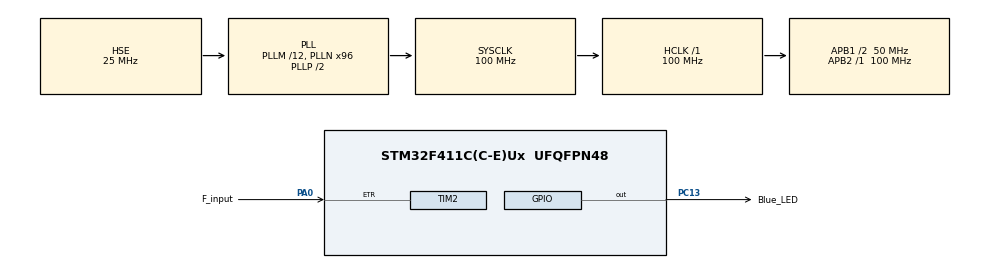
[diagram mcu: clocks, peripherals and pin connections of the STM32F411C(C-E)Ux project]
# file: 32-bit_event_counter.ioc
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Mcu.Family=STM32F4
Mcu.Name=STM32F411C(C-E)Ux
Mcu.Package=UFQFPN48
NVIC.PriorityGroup=NVIC_PRIORITYGROUP_4
NVIC.TIM2_IRQn=true\:0\:0\:false\:false\:true\:true\:true\:true
PA0-WKUP.GPIO_Label=F_input
PA0-WKUP.Signal=S_TIM2_CH1_ETR
PA13.Mode=Serial_Wire
PA13.Signal=SYS_JTMS-SWDIO
PA14.Mode=Serial_Wire
PA14.Signal=SYS_JTCK-SWCLK
PC13-ANTI_TAMP.GPIO_Label=Blue_LED
PC13-ANTI_TAMP.GPIO_ModeDefaultOutputPP=GPIO_MODE_OUTPUT_OD
PC13-ANTI_TAMP.PinState=GPIO_PIN_SET
PC13-ANTI_TAMP.Signal=GPIO_Output
PH0\ -\ OSC_IN.Mode=HSE-External-Oscillator
PH0\ -\ OSC_IN.Signal=RCC_OSC_IN
PH1\ -\ OSC_OUT.Mode=HSE-External-Oscillator
PH1\ -\ OSC_OUT.Signal=RCC_OSC_OUT
ProjectManager.HeapSize=0x200
ProjectManager.StackSize=0x400
ProjectManager.TargetToolchain=STM32CubeIDE
RCC.48MHZClocksFreq_Value=50000000
RCC.AHBFreq_Value=100000000
RCC.APB1CLKDivider=RCC_HCLK_DIV2
RCC.APB1Freq_Value=50000000
RCC.APB1TimFreq_Value=100000000
RCC.APB2Freq_Value=100000000
RCC.APB2TimFreq_Value=100000000
RCC.CortexFreq_Value=100000000
RCC.HCLKFreq_Value=100000000
RCC.HSE_VALUE=25000000
RCC.HSI_VALUE=16000000
RCC.LSE_VALUE=32768
RCC.PLLM=12
RCC.PLLN=96
RCC.PLLSourceVirtual=RCC_PLLSOURCE_HSE
RCC.SYSCLKFreq_VALUE=100000000
RCC.SYSCLKSource=RCC_SYSCLKSOURCE_PLLCLK
RCC.VCOOutputFreq_Value=200000000
SH.S_TIM2_CH1_ETR.0=TIM2_ETR,ClockSourceETR_Mode2
TIM2.AutoReloadPreload=TIM_AUTORELOAD_PRELOAD_DISABLE
TIM2.CounterMode=TIM_COUNTERMODE_DOWN
TIM2.Period=500001
board=custom

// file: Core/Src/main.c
/* USER CODE BEGIN Header */
/**
 *
 * This program sets up Timer 2 (TIM2) to count down from a number defined in CubeMX and to trigger an interrupt when TIM2 = 0
 * the TIM2 interrupt is handled by the function HAL_TIM_PeriodElapsedCallback currently at line 237, which toggles Blue_LED on the module
 *
  ******************************************************************************
  * @file           : main.c
  * @brief          : Main program body
  ******************************************************************************
  * @attention
  *
  * <h2><center>&copy; Copyright (c) 2020 STMicroelectronics.
  * All rights reserved.</center></h2>
  *
  * This software component is licensed by ST under BSD 3-Clause license,
  * the "License"; You may not use this file except in compliance with the
  * License. You may obtain a copy of the License at:
  *                        opensource.org/licenses/BSD-3-Clause
  *
  ******************************************************************************
  */
/* USER CODE END Header */
#include "main.h"

/* USER CODE BEGIN Includes */
#include "stdio.h" //for file and print operations, not needed for this example
/* USER CODE END Includes */

TIM_HandleTypeDef htim2;

void SystemClock_Config(void);
static void MX_GPIO_Init(void);
static void MX_TIM2_Init(void);

/* USER CODE BEGIN 0 */
int Loop_count; //experiment to view this variable in the "Live Expression" section of the debug window that appears when debugging
/* USER CODE END 0 */

int main(void)
{

  /* MCU Configuration--------------------------------------------------------*/

  /* Reset of all peripherals, Initializes the Flash interface and the Systick. */
  HAL_Init();

  /* Configure the system clock */
  SystemClock_Config();

  /* Initialize all configured peripherals */
  MX_GPIO_Init();
  MX_TIM2_Init();
  /* USER CODE BEGIN 2 */

  HAL_TIM_Base_Start_IT(&htim2); //Start Timer 2 in interrupt mode. htim2 is a pointer to a TIM_HandleTypeDef structure that contains the configuration information for TIM module.

  /* USER CODE END 2 */

  /* Infinite loop */
  /* USER CODE BEGIN WHILE */
  while (1)
  {
	//experiment to view this variable in the "Live Expression" section of the debug window that appears when debugging

	Loop_count++; //increment variable Loop_count
    HAL_Delay(500); //Delay 0.5 Seconds

    /* USER CODE END WHILE */

  }
}

void SystemClock_Config(void)
{
  RCC_OscInitTypeDef RCC_OscInitStruct = {0};
  RCC_ClkInitTypeDef RCC_ClkInitStruct = {0};

  /** Configure the main internal regulator output voltage
  */
  __HAL_RCC_PWR_CLK_ENABLE();
  __HAL_PWR_VOLTAGESCALING_CONFIG(PWR_REGULATOR_VOLTAGE_SCALE1);

  /** Initializes the RCC Oscillators according to the specified parameters
  * in the RCC_OscInitTypeDef structure.
  */
  RCC_OscInitStruct.OscillatorType = RCC_OSCILLATORTYPE_HSE;
  RCC_OscInitStruct.HSEState = RCC_HSE_ON;
  RCC_OscInitStruct.PLL.PLLState = RCC_PLL_ON;
  RCC_OscInitStruct.PLL.PLLSource = RCC_PLLSOURCE_HSE;
  RCC_OscInitStruct.PLL.PLLM = 12;
  RCC_OscInitStruct.PLL.PLLN = 96;
  RCC_OscInitStruct.PLL.PLLP = RCC_PLLP_DIV2;
  RCC_OscInitStruct.PLL.PLLQ = 4;
  if (HAL_RCC_OscConfig(&RCC_OscInitStruct) != HAL_OK)
  {
    Error_Handler();
  }

  /** Initializes the CPU, AHB and APB buses clocks
  */
  RCC_ClkInitStruct.ClockType = RCC_CLOCKTYPE_HCLK|RCC_CLOCKTYPE_SYSCLK
                              |RCC_CLOCKTYPE_PCLK1|RCC_CLOCKTYPE_PCLK2;
  RCC_ClkInitStruct.SYSCLKSource = RCC_SYSCLKSOURCE_PLLCLK;
  RCC_ClkInitStruct.AHBCLKDivider = RCC_SYSCLK_DIV1;
  RCC_ClkInitStruct.APB1CLKDivider = RCC_HCLK_DIV2;
  RCC_ClkInitStruct.APB2CLKDivider = RCC_HCLK_DIV1;

  if (HAL_RCC_ClockConfig(&RCC_ClkInitStruct, FLASH_LATENCY_3) != HAL_OK)
  {
    Error_Handler();
  }
}

static void MX_TIM2_Init(void)
{

  TIM_ClockConfigTypeDef sClockSourceConfig = {0};
  TIM_MasterConfigTypeDef sMasterConfig = {0};

  htim2.Instance = TIM2;
  htim2.Init.Prescaler = 0;
  htim2.Init.CounterMode = TIM_COUNTERMODE_DOWN;
  htim2.Init.Period = 500001;
  htim2.Init.ClockDivision = TIM_CLOCKDIVISION_DIV1;
  htim2.Init.AutoReloadPreload = TIM_AUTORELOAD_PRELOAD_DISABLE;
  if (HAL_TIM_Base_Init(&htim2) != HAL_OK)
  {
    Error_Handler();
  }
  sClockSourceConfig.ClockSource = TIM_CLOCKSOURCE_ETRMODE2;
  sClockSourceConfig.ClockPolarity = TIM_CLOCKPOLARITY_NONINVERTED;
  sClockSourceConfig.ClockPrescaler = TIM_CLOCKPRESCALER_DIV1;
  sClockSourceConfig.ClockFilter = 0;
  if (HAL_TIM_ConfigClockSource(&htim2, &sClockSourceConfig) != HAL_OK)
  {
    Error_Handler();
  }
  sMasterConfig.MasterOutputTrigger = TIM_TRGO_RESET;
  sMasterConfig.MasterSlaveMode = TIM_MASTERSLAVEMODE_DISABLE;
  if (HAL_TIMEx_MasterConfigSynchronization(&htim2, &sMasterConfig) != HAL_OK)
  {
    Error_Handler();
  }

}

static void MX_GPIO_Init(void)
{
  GPIO_InitTypeDef GPIO_InitStruct = {0};

  /* GPIO Ports Clock Enable */
  __HAL_RCC_GPIOC_CLK_ENABLE();
  __HAL_RCC_GPIOH_CLK_ENABLE();
  __HAL_RCC_GPIOA_CLK_ENABLE();

  /*Configure GPIO pin Output Level */
  HAL_GPIO_WritePin(Blue_LED_GPIO_Port, Blue_LED_Pin, GPIO_PIN_SET);

  /*Configure GPIO pin : Blue_LED_Pin */
  GPIO_InitStruct.Pin = Blue_LED_Pin;
  GPIO_InitStruct.Mode = GPIO_MODE_OUTPUT_OD;
  GPIO_InitStruct.Pull = GPIO_NOPULL;
  GPIO_InitStruct.Speed = GPIO_SPEED_FREQ_LOW;
  HAL_GPIO_Init(Blue_LED_GPIO_Port, &GPIO_InitStruct);

}

/* USER CODE BEGIN 4 */
//Note: adding the callback function will show an error until the function in the callback handler is added with the closing semi-colon!
void HAL_TIM_PeriodElapsedCallback(TIM_HandleTypeDef *htim2) //Callback function
//Callback handler
{
	HAL_GPIO_TogglePin(Blue_LED_GPIO_Port, Blue_LED_Pin); //Toggle Blue_LED pin state
}
/* USER CODE END 4 */

void Error_Handler(void)
{
  __disable_irq();
  while (1)
  {
  }
}
